VERSION ""

NS_ :

BS_:

BU_: Vector__XXX

BO_ 20 debugDTC: 5 Vector__XXX
SG_ DTC : 0|32@1+ (1,0) [0|4294967295] "" Vector__XXX
SG_ severity : 32|8@1+ (1,0) [0|255] "" Vector__XXX

BO_ 1703 lib_uds: 8 Vector__XXX
SG_ lib_uds_Mux M : 15|4@0+ (1,0) [0|0] "" Vector__XXX
SG_ isotp_n_ta : 7|8@0+ (1,0) [0|255] "" Vector__XXX
SG_ isotp_bs m3 : 23|8@0+ (1,0) [0|255] "" Vector__XXX
SG_ isotp_fs m3 : 11|4@0+ (1,0) [0|15] "" Vector__XXX
SG_ isotp_n_data_fc m3 : 39|32@0+ (1,0) [0|4294967295] "" Vector__XXX
SG_ isotp_stmin m3 : 31|8@0+ (1,0) [0|255] "ms" Vector__XXX
SG_ isotp_sn m2 : 11|4@0+ (1,0) [0|15] "" Vector__XXX
SG_ isotp_n_data_cf m2 : 23|48@0+ (1,0) [0|281474976710655] "" Vector__XXX
SG_ isotp_ff_dl m1 : 11|12@0+ (1,0) [0|4095] "" Vector__XXX
SG_ isotp_n_data_ff m1 : 31|40@0+ (1,0) [0|1099511627775] "" Vector__XXX
SG_ isotp_n_data_sf m0 : 23|48@0+ (1,0) [0|281474976710655] "" Vector__XXX
SG_ isotp_sf_dl m0 : 11|4@0+ (1,0) [0|15] "" Vector__XXX

BO_ 1447 lib_sdo_tx: 8 Vector__XXX
SG_ lib_sdo_tx_Mux M : 5|3@1+ (1,0) [0|0] "" Vector__XXX
SG_ canopen_sdo_abort_code m4 : 32|32@1+ (1,0) [0|4294967295] "" Vector__XXX
SG_ canopen_sdo_abort_index m4 : 8|16@1+ (1,0) [0|65535] "" Vector__XXX
SG_ canopen_sdo_abort_subindex m4 : 24|8@1+ (1,0) [0|255] "" Vector__XXX
SG_ canopen_sdo_upload_toggle_bit m0 : 4|1@1+ (1,0) [0|1] "" Vector__XXX
SG_ canopen_sdo_seg_data m0 : 8|56@1+ (1,0) [0|7.20575940379279E016] "" Vector__XXX
SG_ canopen_sdo_continue m0 : 0|1@1+ (1,0) [0|1] "" Vector__XXX
SG_ canopen_sdo_number_of_bytes_3 m0 : 1|3@1+ (1,0) [0|7] "" Vector__XXX
SG_ canopen_sdo_download_index m3 : 8|16@1+ (1,0) [0|65535] "" Vector__XXX
SG_ canopen_sdo_download_subindex m3 : 24|8@1+ (1,0) [0|255] "" Vector__XXX
SG_ canopen_sdo_upload_index m2 : 8|16@1+ (1,0) [0|65535] "" Vector__XXX
SG_ canopen_sdo_size_indicator m2 : 0|1@1+ (1,0) [0|1] "" Vector__XXX
SG_ canopen_sdo_data m2 : 32|32@1+ (1,0) [0|4294967295] "" Vector__XXX
SG_ canopen_sdo_transfer_type m2 : 1|1@1+ (1,0) [0|1] "" Vector__XXX
SG_ canopen_sdo_number_of_bytes_2 m2 : 2|2@1+ (1,0) [0|3] "" Vector__XXX
SG_ canopen_sdo_upload_subindex m2 : 24|8@1+ (1,0) [0|255] "" Vector__XXX
SG_ canopen_sdo_download_toggle_bit m1 : 4|1@1+ (1,0) [0|1] "" Vector__XXX

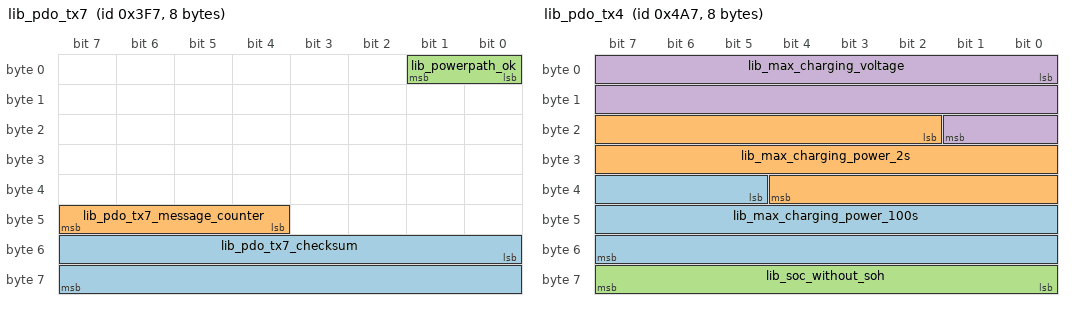
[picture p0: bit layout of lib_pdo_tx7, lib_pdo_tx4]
BO_ 1015 lib_pdo_tx7: 8 Vector__XXX
SG_ lib_pdo_tx7_checksum : 48|16@1+ (1,0) [0|65535] "" Vector__XXX
SG_ lib_pdo_tx7_message_counter : 44|4@1+ (1,0) [0|15] "" Vector__XXX
SG_ lib_powerpath_ok : 0|2@1+ (1,0) [0|3] "" Vector__XXX

BO_ 759 lib_pdo_tx6: 8 Vector__XXX
SG_ lib_max_charging_current_2s : 0|18@1+ (0.01,0) [0|2621.39] "A" Vector__XXX
SG_ lib_max_charging_current_100s : 18|18@1+ (0.01,0) [0|2621.39] "A" Vector__XXX

BO_ 503 lib_pdo_tx5: 8 Vector__XXX
SG_ lib_max_discharging_current_2s : 0|18@1+ (0.01,0) [0|2621.39] "A" Vector__XXX
SG_ lib_max_discharging_current_100s : 18|18@1+ (0.01,0) [0|2621.39] "A" Vector__XXX

BO_ 1191 lib_pdo_tx4: 8 Vector__XXX
SG_ lib_max_charging_power_100s : 37|19@1+ (1,0) [0|524283] "W" Vector__XXX
SG_ lib_max_charging_power_2s : 18|19@1+ (1,0) [0|524283] "W" Vector__XXX
SG_ lib_soc_without_soh : 56|8@1+ (0.5,0) [0|100] "%" Vector__XXX
SG_ lib_max_charging_voltage : 0|18@1+ (0.01,0) [0|2621.39] "V" Vector__XXX

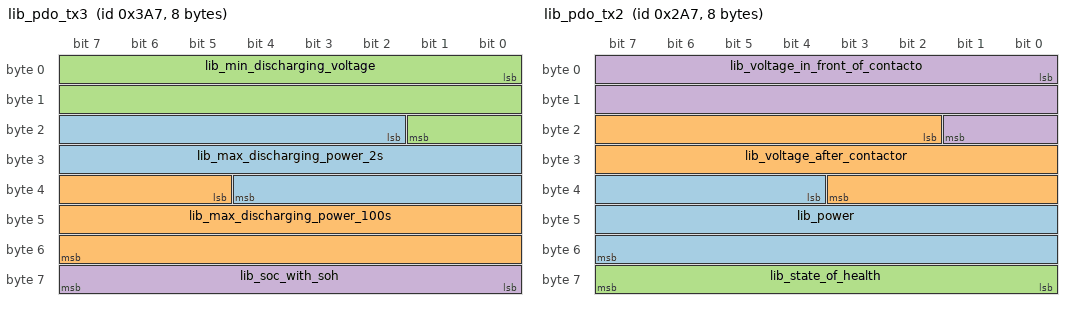
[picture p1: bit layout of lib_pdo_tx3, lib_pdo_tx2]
BO_ 935 lib_pdo_tx3: 8 Vector__XXX
SG_ lib_max_discharging_power_2s : 18|19@1+ (1,0) [0|524283] "W" Vector__XXX
SG_ lib_max_discharging_power_100s : 37|19@1+ (1,0) [0|524283] "W" Vector__XXX
SG_ lib_min_discharging_voltage : 0|18@1+ (0.01,0) [0|2621.39] "V" Vector__XXX
SG_ lib_soc_with_soh : 56|8@1+ (0.5,0) [0|100] "%" Vector__XXX

BO_ 679 lib_pdo_tx2: 8 Vector__XXX
SG_ lib_power : 36|20@1+ (1,-524286) [-524286|524285] "W" Vector__XXX
SG_ lib_voltage_after_contactor : 18|18@1+ (0.01,0) [0|2621.39] "V" Vector__XXX
SG_ lib_state_of_health : 56|8@1+ (0.5,0) [0|100] "%" Vector__XXX
SG_ lib_voltage_in_front_of_contacto : 0|18@1+ (0.01,0) [0|2621.39] "V" Vector__XXX

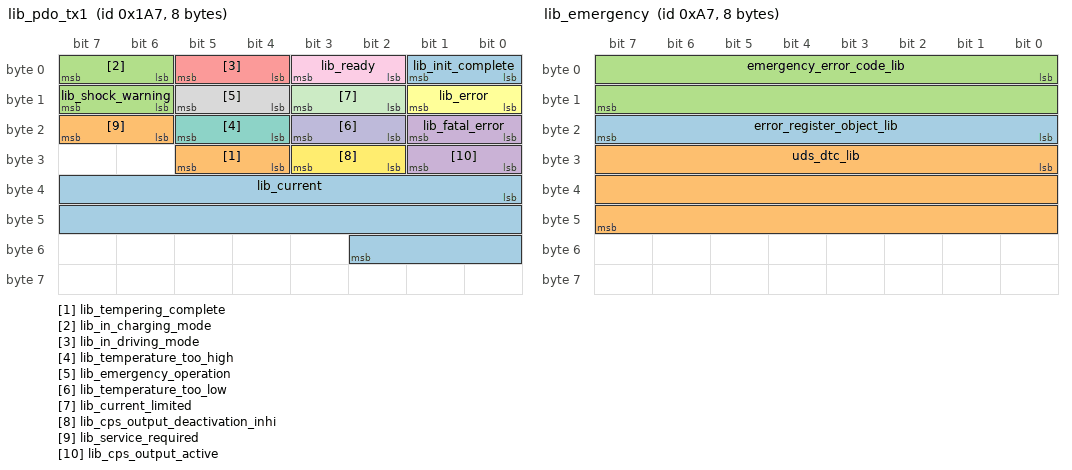
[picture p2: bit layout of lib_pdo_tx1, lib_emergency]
BO_ 423 lib_pdo_tx1: 8 Vector__XXX
SG_ lib_current : 32|19@1+ (0.01,-2621.42) [-2621.42|2621.41] "A" Vector__XXX
SG_ lib_tempering_complete : 28|2@1+ (1,0) [0|3] "" Vector__XXX
SG_ lib_in_charging_mode : 6|2@1+ (1,0) [0|3] "" Vector__XXX
SG_ lib_fatal_error : 16|2@1+ (1,0) [0|3] "" Vector__XXX
SG_ lib_in_driving_mode : 4|2@1+ (1,0) [0|3] "" Vector__XXX
SG_ lib_error : 8|2@1+ (1,0) [0|3] "" Vector__XXX
SG_ lib_temperature_too_high : 20|2@1+ (1,0) [0|3] "" Vector__XXX
SG_ lib_emergency_operation : 12|2@1+ (1,0) [0|3] "" Vector__XXX
SG_ lib_ready : 2|2@1+ (1,0) [0|3] "" Vector__XXX
SG_ lib_temperature_too_low : 18|2@1+ (1,0) [0|3] "" Vector__XXX
SG_ lib_current_limited : 10|2@1+ (1,0) [0|3] "" Vector__XXX
SG_ lib_cps_output_deactivation_inhi : 26|2@1+ (1,0) [0|3] "" Vector__XXX
SG_ lib_init_complete : 0|2@1+ (1,0) [0|3] "" Vector__XXX
SG_ lib_service_required : 22|2@1+ (1,0) [0|3] "" Vector__XXX
SG_ lib_shock_warning : 14|2@1+ (1,0) [0|3] "" Vector__XXX
SG_ lib_cps_output_active : 24|2@1+ (1,0) [0|3] "" Vector__XXX

BO_ 1831 lib_heartbeat: 1 Vector__XXX
SG_ canopen_state_lib : 0|7@1+ (1,0) [0|127] "" Vector__XXX

BO_ 167 lib_emergency: 8 Vector__XXX
SG_ error_register_object_lib : 16|8@1+ (1,0) [0|255] "" Vector__XXX
SG_ uds_dtc_lib : 24|24@1+ (1,0) [0|16777215] "" Vector__XXX
SG_ emergency_error_code_lib : 0|16@1+ (1,0) [0|65535] "" Vector__XXX

BO_ 1759 cps_uds: 8 Vector__XXX
SG_ cps_uds_Mux M : 15|4@0+ (1,0) [0|0] "" Vector__XXX
SG_ isotp_n_ta : 7|8@0+ (1,0) [0|255] "" Vector__XXX
SG_ isotp_fs m3 : 11|4@0+ (1,0) [0|15] "" Vector__XXX
SG_ isotp_bs m3 : 23|8@0+ (1,0) [0|255] "" Vector__XXX
SG_ isotp_n_data_fc m3 : 39|32@0+ (1,0) [0|4294967295] "" Vector__XXX
SG_ isotp_stmin m3 : 31|8@0+ (1,0) [0|255] "ms" Vector__XXX
SG_ isotp_ff_dl m1 : 11|12@0+ (1,0) [0|4095] "" Vector__XXX
SG_ isotp_n_data_ff m1 : 31|40@0+ (1,0) [0|1099511627775] "" Vector__XXX
SG_ isotp_sf_dl m0 : 11|4@0+ (1,0) [0|15] "" Vector__XXX
SG_ isotp_n_data_sf m0 : 23|48@0+ (1,0) [0|281474976710655] "" Vector__XXX
SG_ isotp_n_data_cf m2 : 23|48@0+ (1,0) [0|281474976710655] "" Vector__XXX
SG_ isotp_sn m2 : 11|4@0+ (1,0) [0|15] "" Vector__XXX

BO_ 1805 HeartbtBms: 1 Vector__XXX
SG_ stateBms : 0|7@1+ (1,0) [0|127] "" Vector__XXX

BO_ 1949 DiagRespBms: 8 Vector__XXX
SG_ BmsRsData : 8|56@1+ (1,0) [0|7.20575940379279E016] "" Vector__XXX
SG_ BmsRsPCI : 0|8@1+ (1,0) [0|255] "" Vector__XXX

BO_ 1421 BmsSDOtx: 8 Vector__XXX
SG_ BmsSDOtxData : 0|64@1+ (1,0) [0|1.84467440737096E019] "" Vector__XXX

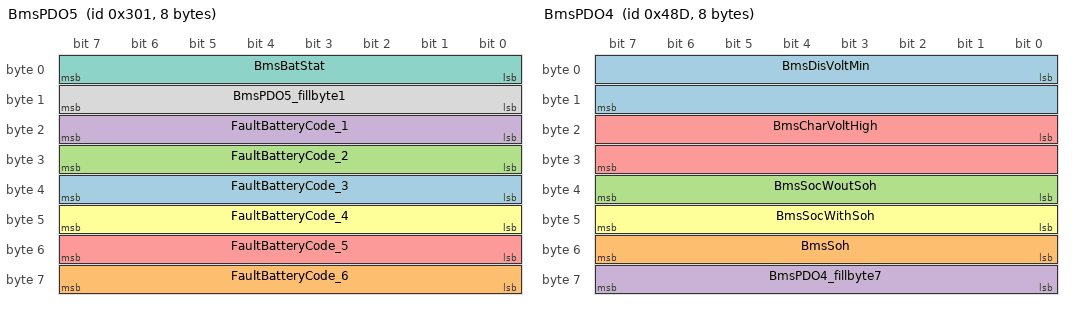
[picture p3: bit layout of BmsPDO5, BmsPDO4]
BO_ 769 BmsPDO5: 8 Vector__XXX
SG_ FaultBatteryCode_3 : 32|8@1+ (1,0) [0|255] "" Vector__XXX
SG_ FaultBatteryCode_6 : 56|8@1+ (1,0) [0|255] "" Vector__XXX
SG_ FaultBatteryCode_2 : 24|8@1+ (1,0) [0|255] "" Vector__XXX
SG_ FaultBatteryCode_1 : 16|8@1+ (1,0) [0|255] "" Vector__XXX
SG_ FaultBatteryCode_5 : 48|8@1+ (1,0) [0|255] "" Vector__XXX
SG_ FaultBatteryCode_4 : 40|8@1+ (1,0) [0|255] "" Vector__XXX
SG_ BmsBatStat : 0|8@1+ (1,0) [0|255] "" Vector__XXX
SG_ BmsPDO5_fillbyte1 : 8|8@1+ (1,0) [0|255] "" Vector__XXX

BO_ 1165 BmsPDO4: 8 Vector__XXX
SG_ BmsDisVoltMin : 0|16@1+ (25,0) [0|1638375] "mV" Vector__XXX
SG_ BmsSoh : 48|8@1+ (1,0) [0|100] "%" Vector__XXX
SG_ BmsSocWoutSoh : 32|8@1+ (1,0) [0|100] "%" Vector__XXX
SG_ BmsPDO4_fillbyte7 : 56|8@1- (1,0) [-128|127] "" Vector__XXX
SG_ BmsCharVoltHigh : 16|16@1+ (25,0) [0|1638375] "mV" Vector__XXX
SG_ BmsSocWithSoh : 40|8@1+ (1,0) [0|100] "%" Vector__XXX

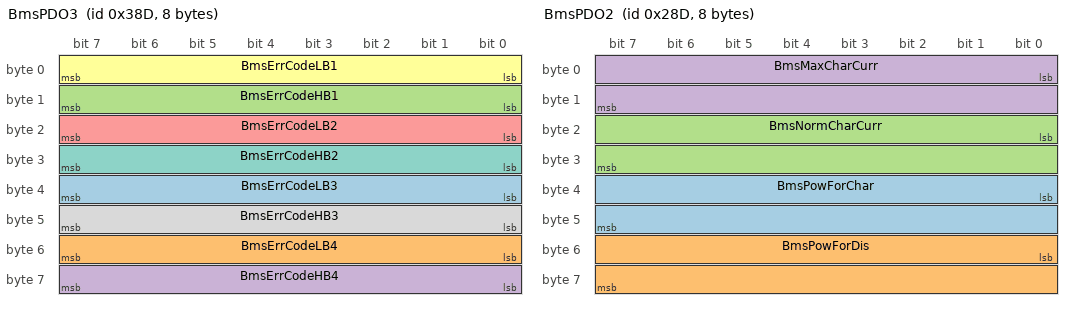
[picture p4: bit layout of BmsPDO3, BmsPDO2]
BO_ 909 BmsPDO3: 8 Vector__XXX
SG_ BmsErrCodeLB3 : 32|8@1+ (1,0) [0|255] "" Vector__XXX
SG_ BmsErrCodeLB4 : 48|8@1+ (1,0) [0|255] "" Vector__XXX
SG_ BmsErrCodeHB1 : 8|8@1+ (1,0) [0|255] "" Vector__XXX
SG_ BmsErrCodeHB4 : 56|8@1+ (1,0) [0|255] "" Vector__XXX
SG_ BmsErrCodeLB2 : 16|8@1+ (1,0) [0|255] "" Vector__XXX
SG_ BmsErrCodeLB1 : 0|8@1+ (1,0) [0|255] "" Vector__XXX
SG_ BmsErrCodeHB2 : 24|8@1+ (1,0) [0|255] "" Vector__XXX
SG_ BmsErrCodeHB3 : 40|8@1+ (1,0) [0|255] "" Vector__XXX

BO_ 653 BmsPDO2: 8 Vector__XXX
SG_ BmsPowForChar : 32|16@1+ (10,0) [0|655350] "W" Vector__XXX
SG_ BmsPowForDis : 48|16@1+ (10,0) [0|655350] "W" Vector__XXX
SG_ BmsNormCharCurr : 16|16@1+ (0.25,0) [0|16383.75] "A" Vector__XXX
SG_ BmsMaxCharCurr : 0|16@1+ (0.25,0) [0|16383.75] "A" Vector__XXX

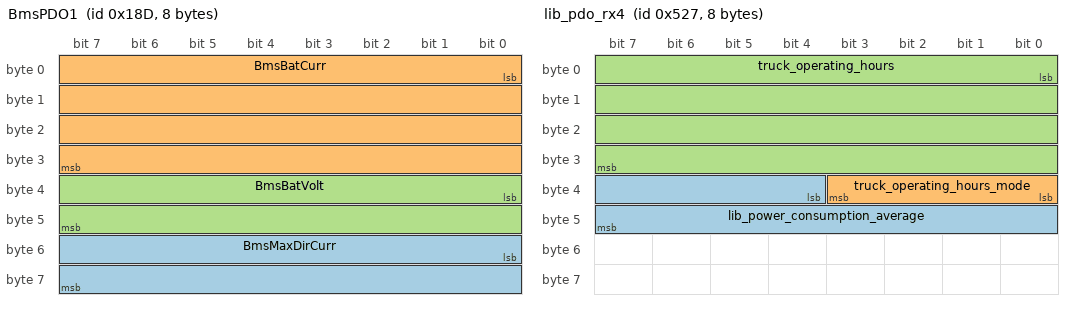
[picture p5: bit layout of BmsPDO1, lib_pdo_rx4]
BO_ 397 BmsPDO1: 8 Vector__XXX
SG_ BmsMaxDirCurr : 48|16@1+ (0.25,0) [0|16383.75] "A" Vector__XXX
SG_ BmsBatCurr : 0|32@1- (1,0) [-4000000|4000000] "mA" Vector__XXX
SG_ BmsBatVolt : 32|16@1+ (2,0) [0|131070] "mV" Vector__XXX

BO_ 1664 dtu_uds: 8 Vector__XXX
SG_ dtu_uds_Mux M : 15|4@0+ (1,0) [0|0] "" Vector__XXX
SG_ isotp_n_ta : 7|8@0+ (1,0) [0|255] "" Vector__XXX
SG_ isotp_n_data_fc m3 : 39|32@0+ (1,0) [0|4294967295] "" Vector__XXX
SG_ isotp_fs m3 : 11|4@0+ (1,0) [0|15] "" Vector__XXX
SG_ isotp_stmin m3 : 31|8@0+ (1,0) [0|255] "ms" Vector__XXX
SG_ isotp_bs m3 : 23|8@0+ (1,0) [0|255] "" Vector__XXX
SG_ isotp_sf_dl m0 : 11|4@0+ (1,0) [0|15] "" Vector__XXX
SG_ isotp_n_data_sf m0 : 23|48@0+ (1,0) [0|281474976710655] "" Vector__XXX
SG_ isotp_sn m2 : 11|4@0+ (1,0) [0|15] "" Vector__XXX
SG_ isotp_n_data_cf m2 : 23|48@0+ (1,0) [0|281474976710655] "" Vector__XXX
SG_ isotp_n_data_ff m1 : 31|40@0+ (1,0) [0|1099511627775] "" Vector__XXX
SG_ isotp_ff_dl m1 : 11|12@0+ (1,0) [0|4095] "" Vector__XXX

BO_ 256 time: 6 Vector__XXX
SG_ canopen_time_of_day_ms : 0|28@1+ (1,0) [0|268435455] "ms" Vector__XXX
SG_ canopen_time_of_day_days : 32|16@1+ (1,0) [0|65535] "d" Vector__XXX

BO_ 1873 obc_heartbeat: 1 Vector__XXX
SG_ canopen_state_obc : 1|7@1+ (1,0) [0|127] "" Vector__XXX

BO_ 0 module_control: 2 Vector__XXX
SG_ canopen_nmt_command_specifier : 0|8@1+ (1,0) [0|255] "" Vector__XXX
SG_ canopen_node_id : 8|8@1+ (1,0) [0|127] "" Vector__XXX

BO_ 1575 lib_sdo_rx: 8 Vector__XXX
SG_ lib_sdo_rx_Mux M : 5|3@1+ (1,0) [0|0] "" Vector__XXX
SG_ canopen_sdo_size_indicator m1 : 0|1@1+ (1,0) [0|1] "" Vector__XXX
SG_ canopen_sdo_number_of_bytes_2 m1 : 2|2@1+ (1,0) [0|3] "" Vector__XXX
SG_ canopen_sdo_download_index m1 : 8|16@1+ (1,0) [0|65535] "" Vector__XXX
SG_ canopen_sdo_transfer_type m1 : 1|1@1+ (1,0) [0|1] "" Vector__XXX
SG_ canopen_sdo_data m1 : 32|32@1+ (1,0) [0|4294967295] "" Vector__XXX
SG_ canopen_sdo_download_subindex m1 : 24|8@1+ (1,0) [0|255] "" Vector__XXX
SG_ canopen_sdo_abort_code m4 : 32|32@1+ (1,0) [0|4294967295] "" Vector__XXX
SG_ canopen_sdo_abort_index m4 : 8|16@1+ (1,0) [0|65535] "" Vector__XXX
SG_ canopen_sdo_abort_subindex m4 : 24|8@1+ (1,0) [0|255] "" Vector__XXX
SG_ canopen_sdo_upload_index m2 : 8|16@1+ (1,0) [0|65535] "" Vector__XXX
SG_ canopen_sdo_upload_subindex m2 : 24|8@1+ (1,0) [0|255] "" Vector__XXX
SG_ canopen_sdo_seg_data m0 : 8|56@1+ (1,0) [0|7.20575940379279E016] "" Vector__XXX
SG_ canopen_sdo_number_of_bytes_3 m0 : 1|3@1+ (1,0) [0|7] "" Vector__XXX
SG_ canopen_sdo_continue m0 : 0|1@1+ (1,0) [0|1] "" Vector__XXX
SG_ canopen_sdo_download_toggle_bit m0 : 4|1@1+ (1,0) [0|1] "" Vector__XXX
SG_ canopen_sdo_upload_toggle_bit m3 : 4|1@1+ (1,0) [0|1] "" Vector__XXX

BO_ 1319 lib_pdo_rx4: 8 Vector__XXX
SG_ lib_power_consumption_average : 36|12@1+ (0.05,-102.3) [-102.3|102.25] "kW" Vector__XXX
SG_ truck_operating_hours_mode : 32|4@1+ (1,0) [0|15] "" Vector__XXX
SG_ truck_operating_hours : 0|32@1+ (1,-36000) [-36000|4294931295] "s" Vector__XXX

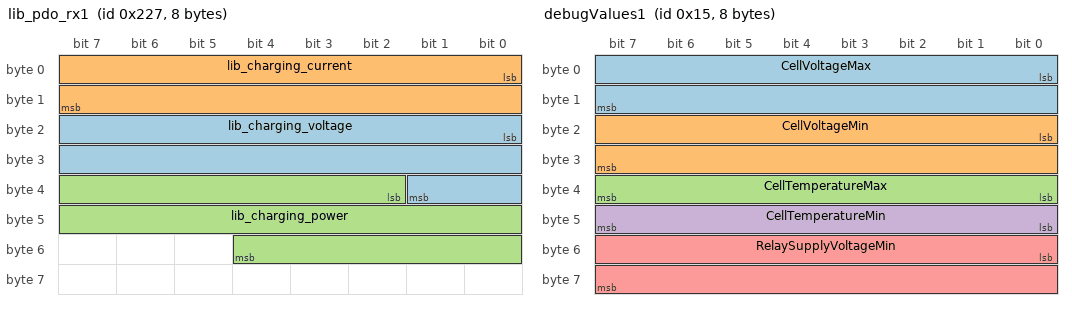
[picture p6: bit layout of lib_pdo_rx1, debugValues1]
BO_ 551 lib_pdo_rx1: 8 Vector__XXX
SG_ lib_charging_voltage : 16|18@1+ (0.01,0) [0|2621.39] "V" Vector__XXX
SG_ lib_charging_current : 0|16@1+ (0.01,0) [0|655.31] "A" Vector__XXX
SG_ lib_charging_power : 34|19@1+ (1,0) [0|524283] "W" Vector__XXX

BO_ 1793 kwpc_heartbeat: 1 Vector__XXX
SG_ canopen_state_kwpc : 1|7@1+ (1,0) [0|127] "" Vector__XXX

BO_ 1866 exc_heartbeat: 1 Vector__XXX
SG_ canopen_state_exc : 0|7@1+ (1,0) [0|127] "" Vector__XXX

BO_ 255 TimeStamp: 4 Vector__XXX
SG_ DateTime : 0|32@1+ (1,0) [0|4294967295] "s" Vector__XXX

BO_ 128 SYNC: 0 Vector__XXX

BO_ 1797 HeartbtLiionCharger: 1 Vector__XXX
SG_ stateLiionCharger : 0|7@1+ (1,0) [0|127] "" Vector__XXX

BO_ 1933 DiagReqBms: 8 Vector__XXX
SG_ BmsRqData : 8|56@1+ (1,0) [0|7.20575940379279E016] "" Vector__XXX
SG_ BmsRqPCI : 0|8@1+ (1,0) [0|255] "" Vector__XXX

BO_ 1549 BmsSDOrx: 8 Vector__XXX
SG_ BmsSDOrxData : 0|64@1+ (1,0) [0|1.84467440737096E019] "" Vector__XXX

BO_ 21 debugValues1: 8 Vector__XXX
SG_ CellVoltageMax : 0|16@1+ (1,0) [0|65535] "" Vector__XXX
SG_ CellVoltageMin : 16|16@1+ (1,0) [0|65535] "" Vector__XXX
SG_ CellTemperatureMax : 32|8@1- (1,0) [-128|127] "" Vector__XXX
SG_ CellTemperatureMin : 40|8@1- (1,0) [-128|127] "" Vector__XXX
SG_ RelaySupplyVoltageMin : 48|16@1+ (1,0) [0|65535] "" Vector__XXX

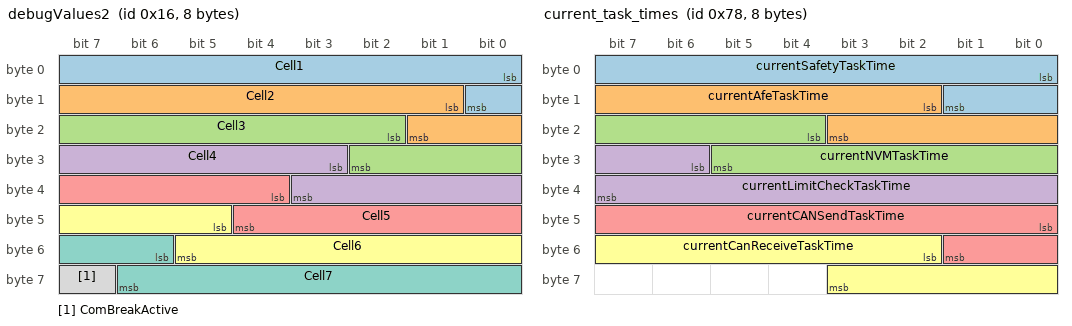
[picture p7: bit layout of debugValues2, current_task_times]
BO_ 22 debugValues2: 8 Vector__XXX
SG_ Cell1 : 0|9@1+ (10,0) [0|5110] "" Vector__XXX
SG_ Cell2 : 9|9@1+ (10,0) [0|5110] "" Vector__XXX
SG_ Cell3 : 18|9@1+ (10,0) [0|5110] "" Vector__XXX
SG_ Cell4 : 27|9@1+ (10,0) [0|5110] "" Vector__XXX
SG_ Cell5 : 36|9@1+ (10,0) [0|5110] "" Vector__XXX
SG_ Cell6 : 45|9@1+ (10,0) [0|5110] "" Vector__XXX
SG_ Cell7 : 54|9@1+ (10,0) [0|5110] "" Vector__XXX
SG_ ComBreakActive : 63|1@1+ (1,0) [0|1] "" Vector__XXX

BO_ 2633967613 lib_xcp_cmd: 0 Vector__XXX

BO_ 2634000381 lib_xcp_res: 0 Vector__XXX

BO_ 120 current_task_times: 8 Vector__XXX
SG_ currentSafetyTaskTime : 0|10@1+ (1,0) [0|1023] "cs" Vector__XXX
SG_ currentAfeTaskTime : 10|10@1+ (1,0) [0|1023] "cs" Vector__XXX
SG_ currentNVMTaskTime : 20|10@1+ (1,0) [0|1023] "cs" Vector__XXX
SG_ currentLimitCheckTaskTime : 30|10@1+ (1,0) [0|1023] "cs" Vector__XXX
SG_ currentCANSendTaskTime : 40|10@1+ (1,0) [0|1023] "cs" Vector__XXX
SG_ currentCanReceiveTaskTime : 50|10@1+ (1,0) [0|1023] "" Vector__XXX

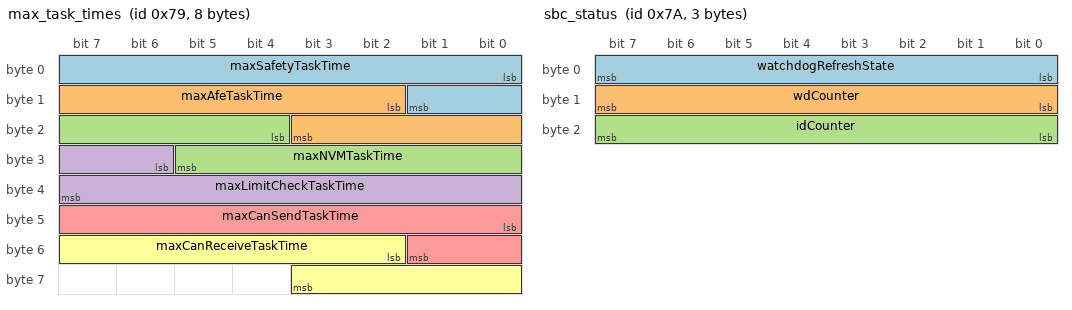
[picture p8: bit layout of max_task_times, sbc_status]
BO_ 121 max_task_times: 8 Vector__XXX
SG_ maxSafetyTaskTime : 0|10@1+ (1,0) [0|1023] "cs" Vector__XXX
SG_ maxAfeTaskTime : 10|10@1+ (1,0) [0|1023] "cs" Vector__XXX
SG_ maxNVMTaskTime : 20|10@1+ (1,0) [0|1023] "cs" Vector__XXX
SG_ maxLimitCheckTaskTime : 30|10@1+ (1,0) [0|1023] "cs" Vector__XXX
SG_ maxCanSendTaskTime : 40|10@1+ (1,0) [0|1023] "cs" Vector__XXX
SG_ maxCanReceiveTaskTime : 50|10@1+ (1,0) [0|1023] "cs" Vector__XXX

BO_ 122 sbc_status: 3 Vector__XXX
SG_ watchdogRefreshState : 0|8@1+ (1,0) [0|255] "" Vector__XXX
SG_ wdCounter : 8|8@1+ (1,0) [0|255] "" Vector__XXX
SG_ idCounter : 16|8@1+ (1,0) [0|255] "" Vector__XXX

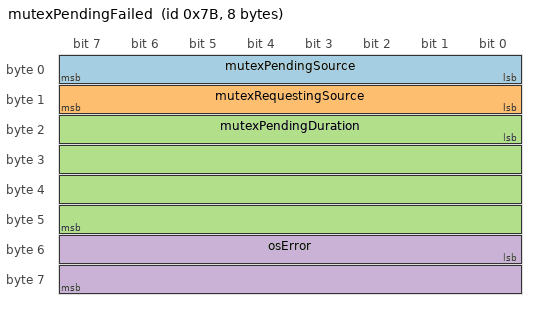
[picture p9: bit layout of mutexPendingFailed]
BO_ 123 mutexPendingFailed: 8 Vector__XXX
SG_ mutexPendingSource : 0|8@1+ (1,0) [0|255] "" Vector__XXX
SG_ mutexRequestingSource : 8|8@1+ (1,0) [0|255] "" Vector__XXX
SG_ mutexPendingDuration : 16|32@1+ (1,0) [0|4294967295] "ms" Vector__XXX
SG_ osError : 48|16@1- (1,0) [-32768|32767] "" Vector__XXX

BO_ 124 mutexPostFailed: 3 Vector__XXX
SG_ mutexPostSource : 0|8@1+ (1,0) [0|255] "" Vector__XXX
SG_ osError : 8|16@1- (1,0) [-32768|32767] "" Vector__XXX

CM_ BO_ 1703 "UDS responses from LIB with KION protocol";
CM_ SG_ 1703 lib_uds_Mux "network protocol control information type (ISO-TP extended addressing)";
CM_ SG_ 1703 isotp_n_ta "network target address (ISO-TP extended addressing)";
CM_ SG_ 1703 isotp_bs "FlowControl BlockSize (ISO-TP extended addressing)";
CM_ SG_ 1703 isotp_fs "FlowControl FlowStatus (ISO-TP extended addressing)";
CM_ SG_ 1703 isotp_n_data_fc "FlowControl Data Field (ISO-TP extended addressing)";
CM_ SG_ 1703 isotp_stmin "FlowControl SeparationTime minimum (ISO-TP extended addressing)";
CM_ SG_ 1703 isotp_sn "ConsecutiveFrame SequenceNumber (ISO-TP extended addressing)";
CM_ SG_ 1703 isotp_n_data_cf "Consecutive Frame Data Field (ISO-TP extended addressing)";
CM_ SG_ 1703 isotp_ff_dl "FirstFrame DataLength (ISO-TP extended addressing)";
CM_ SG_ 1703 isotp_n_data_ff "FirstFrame Data Field (ISO-TP extended addressing)";
CM_ SG_ 1703 isotp_n_data_sf "SingleFrame Data Field (ISO-TP extended addressing)";
CM_ SG_ 1703 isotp_sf_dl "SingleFrame DataLength (ISO-TP extended addressing)";
CM_ BO_ 1447 "SDO Tx, node 0x27 (LIB with KION protocol), SDO clients: KMC, OBC, EXC";
CM_ BO_ 1015 "PDO 7 (Tx), node 0x77 (LIB with KION protocol)";
CM_ BO_ 759 "PDO 6 (Tx), node 0x77 (LIB with KION protocol)";
CM_ BO_ 503 "PDO 5 (Tx), node 0x77 (LIB with KION protocol)";
CM_ BO_ 1191 "PDO 4 (Tx), node 0x27 (LIB with KION protocol)";
CM_ BO_ 935 "PDO 3 (Tx), node 0x27 (LIB with KION protocol)";
CM_ BO_ 679 "PDO 2 (Tx), node 0x27 (LIB with KION protocol)";
CM_ SG_ 679 lib_power "positive values = charging, negative values = discharging";
CM_ SG_ 679 lib_voltage_after_contactor "voltage after battery contactor (as seen from battery), i.e. truck side of contactor";
CM_ SG_ 679 lib_voltage_in_front_of_contacto "voltage in front of battery contactor (as seen from battery), i.e. battery side of contactor";
CM_ BO_ 423 "PDO 1 (Tx), node 0x27 (LIB with KION protocol)";
CM_ SG_ 423 lib_current "positive values = charging, negative values = discharging";
CM_ BO_ 1831 "heartbeat (NMT error control), node 0x27 (LIB with KION protocol)";
CM_ SG_ 1831 canopen_state_lib "CANopen node status of lithium-ion battery (KION protocol)";
CM_ BO_ 167 "emergency (EMCY), node 0x27 (LIB with KION protocol)";
CM_ BO_ 1759 "UDS responses from CPS in LIB with KION protocol";
CM_ SG_ 1759 cps_uds_Mux "network protocol control information type (ISO-TP extended addressing)";
CM_ SG_ 1759 isotp_n_ta "network target address (ISO-TP extended addressing)";
CM_ SG_ 1759 isotp_fs "FlowControl FlowStatus (ISO-TP extended addressing)";
CM_ SG_ 1759 isotp_bs "FlowControl BlockSize (ISO-TP extended addressing)";
CM_ SG_ 1759 isotp_n_data_fc "FlowControl Data Field (ISO-TP extended addressing)";
CM_ SG_ 1759 isotp_stmin "FlowControl SeparationTime minimum (ISO-TP extended addressing)";
CM_ SG_ 1759 isotp_ff_dl "FirstFrame DataLength (ISO-TP extended addressing)";
CM_ SG_ 1759 isotp_n_data_ff "FirstFrame Data Field (ISO-TP extended addressing)";
CM_ SG_ 1759 isotp_sf_dl "SingleFrame DataLength (ISO-TP extended addressing)";
CM_ SG_ 1759 isotp_n_data_sf "SingleFrame Data Field (ISO-TP extended addressing)";
CM_ SG_ 1759 isotp_n_data_cf "Consecutive Frame Data Field (ISO-TP extended addressing)";
CM_ SG_ 1759 isotp_sn "ConsecutiveFrame SequenceNumber (ISO-TP extended addressing)";
CM_ BO_ 1805 "Network Management, Error Control, Battery management system Heartbeat";
CM_ BO_ 1421 "CAN Open: Data for Service data object (SDO) send by BMS";
CM_ SG_ 1421 BmsSDOtxData "CAN Open: Data for Service data object (SDO) send by BMS";
CM_ SG_ 769 FaultBatteryCode_3 "Fault Battery Code # 3";
CM_ SG_ 769 FaultBatteryCode_6 "Fault Battery Code # 6";
CM_ SG_ 769 FaultBatteryCode_2 "Fault Battery Code # 2";
CM_ SG_ 769 FaultBatteryCode_1 "Fault Battery Code # 1";
CM_ SG_ 769 FaultBatteryCode_5 "Fault Battery Code # 5";
CM_ SG_ 769 FaultBatteryCode_4 "Fault Battery Code # 4";
CM_ SG_ 769 BmsPDO5_fillbyte1 "place holder to reserve signal position for future use";
CM_ SG_ 1165 BmsDisVoltMin "Minimum allowed voltage during discharge";
CM_ SG_ 1165 BmsPDO4_fillbyte7 "place holder to reserve signal position for future use";
CM_ SG_ 1165 BmsCharVoltHigh "Highest allowed voltage during charging";
CM_ SG_ 909 BmsErrCodeLB3 "BmsErrorCode3 (unsigned16, low byte)";
CM_ SG_ 909 BmsErrCodeLB4 "BmsErrorCode4 (unsigned16, low byte)";
CM_ SG_ 909 BmsErrCodeHB1 "BmsErrorCode1 (unsigned16, high byte)";
CM_ SG_ 909 BmsErrCodeHB4 "BmsErrorCode4 (unsigned16, high byte)";
CM_ SG_ 909 BmsErrCodeLB2 "BmsErrorCode2 (unsigned16, low byte)";
CM_ SG_ 909 BmsErrCodeLB1 "BmsErrorCode1 (unsigned16, low byte)";
CM_ SG_ 909 BmsErrCodeHB2 "BmsErrorCode2 (unsigned16, high byte)";
CM_ SG_ 909 BmsErrCodeHB3 "BmsErrorCode3 (unsigned16, high byte)";
CM_ SG_ 653 BmsPowForChar "Power forecasting: charging [W] = BmsPowForChar * 10";
CM_ SG_ 653 BmsPowForDis "Power forecasting: charging [W] = BmsPowForChar * 10";
CM_ SG_ 653 BmsNormCharCurr "Normal charge current [A] = BmsNormCharCurr * 0.25";
CM_ SG_ 653 BmsMaxCharCurr "Maximal charge current [A] = BmsMaxCharCurr * 0.25";
CM_ BO_ 1664 "UDS requests from DTU";
CM_ SG_ 1664 dtu_uds_Mux "network protocol control information type (ISO-TP extended addressing)";
CM_ SG_ 1664 isotp_n_ta "network target address (ISO-TP extended addressing)";
CM_ SG_ 1664 isotp_n_data_fc "FlowControl Data Field (ISO-TP extended addressing)";
CM_ SG_ 1664 isotp_fs "FlowControl FlowStatus (ISO-TP extended addressing)";
CM_ SG_ 1664 isotp_stmin "FlowControl SeparationTime minimum (ISO-TP extended addressing)";
CM_ SG_ 1664 isotp_bs "FlowControl BlockSize (ISO-TP extended addressing)";
CM_ SG_ 1664 isotp_sf_dl "SingleFrame DataLength (ISO-TP extended addressing)";
CM_ SG_ 1664 isotp_n_data_sf "SingleFrame Data Field (ISO-TP extended addressing)";
CM_ SG_ 1664 isotp_sn "ConsecutiveFrame SequenceNumber (ISO-TP extended addressing)";
CM_ SG_ 1664 isotp_n_data_cf "Consecutive Frame Data Field (ISO-TP extended addressing)";
CM_ SG_ 1664 isotp_n_data_ff "FirstFrame Data Field (ISO-TP extended addressing)";
CM_ SG_ 1664 isotp_ff_dl "FirstFrame DataLength (ISO-TP extended addressing)";
CM_ BO_ 256 "time stamp (TIME)";
CM_ BO_ 1873 "heartbeat (NMT error control), node 0x51 (OBC)";
CM_ SG_ 1873 canopen_state_obc "CANopen node status of on-board charger";
CM_ BO_ 0 "network management (NMT)";
CM_ BO_ 1575 "SDO Rx, node 0x27 (LIB with KION protocol), SDO clients: KMC, OBC, EXC";
CM_ BO_ 1319 "PDO 4 (Rx), node 0x27 (LIB with KION protocol)";
CM_ SG_ 1319 lib_power_consumption_average "for estimation of remaining charging time until end of shift";
CM_ SG_ 1319 truck_operating_hours_mode "main truck hour meter counting mode";
CM_ SG_ 1319 truck_operating_hours "main truck hour meter";
CM_ BO_ 551 "PDO 1 (Rx), node 0x27 (LIB with KION protocol)";
CM_ SG_ 551 lib_charging_voltage "output voltage of charger";
CM_ SG_ 551 lib_charging_current "output current of charger";
CM_ SG_ 551 lib_charging_power "output power of charger";
CM_ BO_ 1793 "heartbeat (NMT error control), node 0x01 (KWPC)";
CM_ SG_ 1793 canopen_state_kwpc "CANopen node status of KION Motion Controller";
CM_ BO_ 1866 "heartbeat (NMT error control), node 0x4A (EXC)";
CM_ SG_ 1866 canopen_state_exc "CANopen node status of the external battery charger";
CM_ BO_ 255 "Linde proprietary timestamp message (for LIB with Linde SAFT protocol)";
CM_ BO_ 128 "CANopen SYNC message (for LIB with Linde BMZ protocol)";
CM_ BO_ 1797 "Network Management, Error Control,  liion battery charger Heartbeat";
CM_ BO_ 1549 "CAN Open: Service data object (SDO) send by KWPC";
CM_ SG_ 1549 BmsSDOrxData "CAN Open: Data for Service data object (SDO) send by LAC";
CM_ BO_ 120 "shows times of every task in taskAliveMonitor";
CM_ SG_ 120 currentSafetyTaskTime "current cycle time of safety task";
CM_ SG_ 120 currentAfeTaskTime "current cycle time of afe task";
CM_ SG_ 120 currentNVMTaskTime "current cycle time of nvm task";
CM_ SG_ 120 currentLimitCheckTaskTime "current cycle time of limitCheck task";
CM_ SG_ 120 currentCANSendTaskTime "current cycle time of can send task";
CM_ SG_ 120 currentCanReceiveTaskTime "current cycle time of can receive task";
CM_ SG_ 121 maxSafetyTaskTime "max cycle time of safety task";
CM_ SG_ 121 maxAfeTaskTime "max cycle time of afe task";
CM_ SG_ 121 maxNVMTaskTime "max cycle time of NVM task";
CM_ SG_ 121 maxLimitCheckTaskTime "max cycle time of limitCheck task";
CM_ SG_ 121 maxCanSendTaskTime "max cycle time of can send task";
CM_ SG_ 121 maxCanReceiveTaskTime "max cycle time of can receive task";
CM_ SG_ 122 watchdogRefreshState "state of watchdog during SW reset call";
CM_ SG_ 122 wdCounter "watchdog counter";
CM_ SG_ 122 idCounter "idCounter of failed task in taskAliveMonitor";
CM_ BO_ 123 "mutex analysis data";
CM_ SG_ 123 mutexPendingSource "source of mutex that is currently pending";
CM_ SG_ 123 mutexRequestingSource "source of mutex pend request that is currently unsuccessful";
CM_ SG_ 123 mutexPendingDuration "duration of current pending time of the mutex in ms";
CM_ SG_ 123 osError "osError that was returned during mutex pend request";
CM_ BO_ 124 "failed mutex post analysis Signal";
CM_ SG_ 124 mutexPostSource "source of mutex post request";
CM_ SG_ 124 osError "OS error that was thrown during mutex post request";

BA_DEF_  "BusType" STRING ;
BA_DEF_ BO_  "GenMsgCycleTime" INT 0 65535;
BA_DEF_ SG_  "GenSigStartValue" FLOAT -3.4E+038 3.4E+038;

BA_DEF_DEF_  "BusType" "CAN";
BA_DEF_DEF_  "GenMsgCycleTime" 0;
BA_DEF_DEF_  "GenSigStartValue" 0;

BA_ "GenMsgCycleTime" BO_ 120 10;

BA_ "GenSigStartValue" SG_ 1015 lib_powerpath_ok 3;
BA_ "GenSigStartValue" SG_ 679 lib_power 524286;
BA_ "GenSigStartValue" SG_ 423 lib_tempering_complete 3;
BA_ "GenSigStartValue" SG_ 423 lib_in_charging_mode 3;
BA_ "GenSigStartValue" SG_ 423 lib_fatal_error 3;
BA_ "GenSigStartValue" SG_ 423 lib_in_driving_mode 3;
BA_ "GenSigStartValue" SG_ 423 lib_error 3;
BA_ "GenSigStartValue" SG_ 423 lib_temperature_too_high 3;
BA_ "GenSigStartValue" SG_ 423 lib_emergency_operation 3;
BA_ "GenSigStartValue" SG_ 423 lib_ready 3;
BA_ "GenSigStartValue" SG_ 423 lib_temperature_too_low 3;
BA_ "GenSigStartValue" SG_ 423 lib_current_limited 3;
BA_ "GenSigStartValue" SG_ 423 lib_cps_output_deactivation_inhi 3;
BA_ "GenSigStartValue" SG_ 423 lib_init_complete 3;
BA_ "GenSigStartValue" SG_ 423 lib_service_required 3;
BA_ "GenSigStartValue" SG_ 423 lib_shock_warning 3;
BA_ "GenSigStartValue" SG_ 423 lib_cps_output_active 3;
BA_ "GenSigStartValue" SG_ 1831 canopen_state_lib 127;
BA_ "GenSigStartValue" SG_ 1319 lib_power_consumption_average 2046;
BA_ "GenSigStartValue" SG_ 1319 truck_operating_hours_mode 15;
BA_ "GenSigStartValue" SG_ 1319 truck_operating_hours 36000;

VAL_ 1703 lib_uds_Mux 3 "flow control" 2 "consecutive frame" 1 "first frame" 0 "single frame" 7 "reserved 4" 6 "reserved 3" 5 "reserved 2" 4 "reserved 1";
VAL_ 1447 lib_sdo_tx_Mux 4 "abort transfer request" 0 "upload segment response" 3 "initiate download response" 2 "initiate upload response" 1 "download segment response" 7 "reserved" 6 "block upload" 5 "block download";
VAL_ 1759 cps_uds_Mux 3 "flow control" 1 "first frame" 0 "single frame" 2 "consecutive frame" 7 "reserved 4" 6 "reserved 3" 5 "reserved 2" 4 "reserved 1";
VAL_ 1664 dtu_uds_Mux 3 "flow control" 0 "single frame" 2 "consecutive frame" 1 "first frame" 7 "reserved 4" 6 "reserved 3" 5 "reserved 2" 4 "reserved 1";
VAL_ 1575 lib_sdo_rx_Mux 1 "initiate download request" 4 "abort transfer request" 2 "initiate upload request" 0 "download segment request" 3 "upload segment request" 7 "reserved" 6 "block download" 5 "block upload";
VAL_ 1703 isotp_n_ta 254 "functional address" 95 "cps" 81 "obc" 80 "knc" 72 "kwc_b" 70 "tpi" 68 "kap_r" 39 "lib" 38 "tu" 37 "kec" 33 "kcs" 32 "kcu" 31 "kap_k" 22 "dou" 20 "rpb" 19 "kwc_a" 18 "kae" 16 "ksc" 13 "kpc_l2" 12 "kpc_l1" 11 "kpc_tr" 10 "kpc_tl" 9 "kpc_u" 5 "kbc" 1 "kmc/kwpc" 0 "dtu";
VAL_ 1703 isotp_fs 15 "reserved 13" 14 "reserved 12" 13 "reserved 11" 12 "reserved 10" 11 "reserved 9" 10 "reserved 8" 9 "reserved 7" 8 "reserved 6" 7 "reserved 5" 6 "reserved 4" 5 "reserved 3" 4 "reserved 2" 3 "reserved 1" 2 "overflow" 1 "wait" 0 "continue to send";
VAL_ 1447 canopen_sdo_abort_code 134217764 "no data available" 134217763 "object dictionary dynamic generation fails or no dictionary present" 134217762 "data cannot be stored to the application because of the present device state" 134217761 "data cannot be stored to the application because of local control" 134217760 "data cannot be stored to the application" 134217728 "general error" 101318691 "resource not available: SDO connection" 101253174 "maximum value is less than minimum value" 101253170 "value of parameter written too low" 101253169 "value of parameter written too high" 101253168 "invalid value for parameter" 101253137 "subindex does not exist" 101122067 "data type mismatch, length of parameter too low" 101122066 "data type mismatch, length of parameter too high" 101122064 "data type mismatch, length of parameter does not match" 101056512 "access failed due to an hardware error" 100925511 "general internal incompatibility in the device" 100925507 "general parameter incompatibility reason" 100925506 "PDO length exceeded by mapping"
100925505 "object cannot be mapped to the PDO" 100794368 "object does not exist in the object dictionary" 100728834 "attempt to write a read only object" 100728833 "attempt to read a write only object" 100728832 "unsupported access to an object" 84148229 "out of memory" 84148228 "CRC error" 84148227 "invalid sequence number" 84148226 "invalid block size" 84148225 "client/server command specifier not valid or unknown" 84148224 "SDO protocol timed out" 84082688 "toggle bit not alternated";
VAL_ 1447 canopen_sdo_continue 1 "no more segments to be downloaded" 0 "more segments to be downloaded";
VAL_ 1447 canopen_sdo_number_of_bytes_3 7 "data length 0 byte" 6 "data length 1 byte" 5 "data length 2 byte" 4 "data length 3 byte" 3 "data length 4 byte" 2 "data length 5 byte" 1 "data length 6 byte" 0 "data length 7 byte";
VAL_ 1447 canopen_sdo_size_indicator 1 "data set size is indicated" 0 "data set size is not indicated";
VAL_ 1447 canopen_sdo_transfer_type 1 "expedited transfer" 0 "normal transfer";
VAL_ 1447 canopen_sdo_number_of_bytes_2 3 "data length 1 byte" 2 "data length 2 byte" 1 "data length 3 byte" 0 "data length 4 byte";
VAL_ 1015 lib_powerpath_ok 3 "signal not available" 2 "signal error" 1 "true/on" 0 "false/off";
VAL_ 759 lib_max_charging_current_2s 262143 "signal not available" 262142 "signal error" 262141 "reserved 2" 262140 "reserved 1";
VAL_ 759 lib_max_charging_current_100s 262143 "signal not available" 262142 "signal error" 262141 "reserved 2" 262140 "reserved 1";
VAL_ 503 lib_max_discharging_current_2s 262143 "signal not available" 262142 "signal error" 262141 "reserved 2" 262140 "reserved 1";
VAL_ 503 lib_max_discharging_current_100s 262143 "signal not available" 262142 "signal error" 262141 "reserved 2" 262140 "reserved 1";
VAL_ 1191 lib_max_charging_power_100s 524287 "signal not available" 524286 "signal error" 524285 "reserved 2" 524284 "reserved 1";
VAL_ 1191 lib_max_charging_power_2s 524287 "signal not available" 524286 "signal error" 524285 "reserved 2" 524284 "reserved 1";
VAL_ 1191 lib_soc_without_soh 255 "signal not available" 254 "signal error" 253 "reserved 2" 252 "reserved 1";
VAL_ 1191 lib_max_charging_voltage 262143 "signal not available" 262142 "signal error" 262141 "reserved 2" 262140 "reserved 1";
VAL_ 935 lib_max_discharging_power_2s 524287 "signal not available" 524286 "signal error" 524285 "reserved 2" 524284 "reserved 1";
VAL_ 935 lib_max_discharging_power_100s 524287 "signal not available" 524286 "signal error" 524285 "reserved 2" 524284 "reserved 1";
VAL_ 935 lib_min_discharging_voltage 262143 "signal not available" 262142 "signal error" 262141 "reserved 2" 262140 "reserved 1";
VAL_ 935 lib_soc_with_soh 255 "signal not available" 254 "signal error" 253 "reserved 2" 252 "reserved 1";
VAL_ 679 lib_power 1048575 "signal not available" 1048574 "signal error" 1048573 "reserved 2" 1048572 "reserved 1";
VAL_ 679 lib_voltage_after_contactor 262143 "signal not available" 262142 "signal error" 262141 "reserved 2" 262140 "reserved 1";
VAL_ 679 lib_state_of_health 255 "signal not available" 254 "signal error" 253 "reserved 2" 252 "reserved 1";
VAL_ 679 lib_voltage_in_front_of_contacto 262143 "signal not available" 262142 "signal error" 262141 "reserved 2" 262140 "reserved 1";
VAL_ 423 lib_current 524287 "signal not available" 524286 "signal error" 524285 "reserved 2" 524284 "reserved 1";
VAL_ 423 lib_tempering_complete 3 "signal not available" 2 "signal error" 1 "true/on" 0 "false/off";
VAL_ 423 lib_in_charging_mode 3 "signal not available" 2 "signal error" 1 "true/on" 0 "false/off";
VAL_ 423 lib_fatal_error 3 "signal not available" 2 "signal error" 1 "true/on" 0 "false/off";
VAL_ 423 lib_in_driving_mode 3 "signal not available" 2 "signal error" 1 "true/on" 0 "false/off";
VAL_ 423 lib_error 3 "signal not available" 2 "signal error" 1 "true/on" 0 "false/off";
VAL_ 423 lib_temperature_too_high 3 "signal not available" 2 "signal error" 1 "true/on" 0 "false/off";
VAL_ 423 lib_emergency_operation 3 "signal not available" 2 "signal error" 1 "true/on" 0 "false/off";
VAL_ 423 lib_ready 3 "signal not available" 2 "signal error" 1 "true/on" 0 "false/off";
VAL_ 423 lib_temperature_too_low 3 "signal not available" 2 "signal error" 1 "true/on" 0 "false/off";
VAL_ 423 lib_current_limited 3 "signal not available" 2 "signal error" 1 "true/on" 0 "false/off";
VAL_ 423 lib_cps_output_deactivation_inhi 3 "signal not available" 2 "signal error" 1 "true/on" 0 "false/off";
VAL_ 423 lib_init_complete 3 "signal not available" 2 "signal error" 1 "true/on" 0 "false/off";
VAL_ 423 lib_service_required 3 "signal not available" 2 "signal error" 1 "true/on" 0 "false/off";
VAL_ 423 lib_shock_warning 3 "signal not available" 2 "signal error" 1 "true/on" 0 "false/off";
VAL_ 423 lib_cps_output_active 3 "signal not available" 2 "signal error" 1 "true/on" 0 "false/off";
VAL_ 1831 canopen_state_lib 127 "pre-operational" 5 "operational" 4 "stopped" 0 "bootup";
VAL_ 1759 isotp_n_ta 254 "functional address" 95 "cps" 81 "obc" 80 "knc" 72 "kwc_b" 70 "tpi" 68 "kap_r" 39 "lib" 38 "tu" 37 "kec" 33 "kcs" 32 "kcu" 31 "kap_k" 22 "dou" 20 "rpb" 19 "kwc_a" 18 "kae" 16 "ksc" 13 "kpc_l2" 12 "kpc_l1" 11 "kpc_tr" 10 "kpc_tl" 9 "kpc_u" 5 "kbc" 1 "kmc/kwpc" 0 "dtu";
VAL_ 1759 isotp_fs 15 "reserved 13" 14 "reserved 12" 13 "reserved 11" 12 "reserved 10" 11 "reserved 9" 10 "reserved 8" 9 "reserved 7" 8 "reserved 6" 7 "reserved 5" 6 "reserved 4" 5 "reserved 3" 4 "reserved 2" 3 "reserved 1" 2 "overflow" 1 "wait" 0 "continue to send";
VAL_ 1805 stateBms 127 "PREOPERATIONAL" 5 "OPERATIONAL" 4 "STOPPED" 0 "BOOTUP";
VAL_ 769 FaultBatteryCode_3 7 "fault code status n� 24" 6 "fault code status n� 23" 5 "fault code status n� 22" 4 "fault code status n� 21" 3 "fault code status n� 20" 2 "fault code status n� 19" 1 "fault code status n� 18" 0 "fault code status n� 17";
VAL_ 769 FaultBatteryCode_6 7 "fault code status n� 48" 6 "fault code status n� 47" 5 "fault code status n� 46" 4 "fault code status n� 45" 3 "fault code status n� 44" 2 "fault code status n� 43" 1 "fault code status n� 42" 0 "fault code status n� 41";
VAL_ 769 FaultBatteryCode_2 7 "fault code status n� 16" 6 "fault code status n� 15" 5 "fault code status n� 14" 4 "fault code status n� 13" 3 "fault code status n� 12" 2 "fault code status n� 11" 1 "fault code status n� 10" 0 "fault code status n� 9";
VAL_ 769 FaultBatteryCode_1 7 "fault code status n� 8" 6 "fault code status n� 7" 5 "fault code status n� 6" 4 "fault code status n� 5" 3 "fault code status n� 4" 2 "fault code status n� 3" 1 "fault code status n� 2" 0 "fault code status n� 1";
VAL_ 769 FaultBatteryCode_5 7 "fault code status n� 40" 6 "fault code status n� 39" 5 "fault code status n� 38" 4 "fault code status n� 37" 3 "fault code status n� 36" 2 "fault code status n� 35" 1 "fault code status n� 34" 0 "fault code status n� 33";
VAL_ 769 FaultBatteryCode_4 7 "fault code status n� 32" 6 "fault code status n� 31" 5 "fault code status n� 30" 4 "fault code status n� 29" 3 "fault code status n� 28" 2 "fault code status n� 27" 1 "fault code status n� 26" 0 "fault code status n� 25";
VAL_ 769 BmsBatStat 9 "-> 0xFF reserved" 8 "Charge mode in regeneration" 7 "Charge- or On-board charge-mode" 6 "After run mode (self-test)" 5 "Safe mode (system disconnected)" 4 "Init mode (before precharge)" 3 "Standby mode" 2 "Pre-charge mode  " 1 "Nominal mode " 0 "Reserved";
VAL_ 1664 isotp_n_ta 254 "functional address" 95 "cps" 81 "obc" 80 "knc" 72 "kwc_b" 70 "tpi" 68 "kap_r" 39 "lib" 38 "tu" 37 "kec" 33 "kcs" 32 "kcu" 31 "kap_k" 22 "dou" 20 "rpb" 19 "kwc_a" 18 "kae" 16 "ksc" 13 "kpc_l2" 12 "kpc_l1" 11 "kpc_tr" 10 "kpc_tl" 9 "kpc_u" 5 "kbc" 1 "kmc/kwpc" 0 "dtu";
VAL_ 1664 isotp_fs 15 "reserved 13" 14 "reserved 12" 13 "reserved 11" 12 "reserved 10" 11 "reserved 9" 10 "reserved 8" 9 "reserved 7" 8 "reserved 6" 7 "reserved 5" 6 "reserved 4" 5 "reserved 3" 4 "reserved 2" 3 "reserved 1" 2 "overflow" 1 "wait" 0 "continue to send";
VAL_ 1873 canopen_state_obc 127 "pre-operational" 5 "operational" 4 "stopped" 0 "bootup";
VAL_ 0 canopen_nmt_command_specifier 130 "reset communication" 129 "reset node" 128 "enter pre-operational" 2 "stop remote node" 1 "start remote node";
VAL_ 0 canopen_node_id 81 "obc" 80 "knc" 76 "tci" 74 "exc" 70 "tpi" 68 "kap_r" 39 "lib" 38 "tu" 37 "kec" 33 "kcs" 32 "kcu" 31 "kap_k" 29 "lhs_r_b" 28 "lhs_r_a" 22 "dou" 20 "rpb" 18 "kae" 16 "ksc" 13 "kpc_l2" 12 "kpc_l1" 11 "kpc_tr" 10 "kpc_tl" 9 "kpc_u" 5 "kbc" 1 "kmc" 0 "all nodes";
VAL_ 1575 canopen_sdo_size_indicator 1 "data set size is indicated" 0 "data set size is not indicated";
VAL_ 1575 canopen_sdo_number_of_bytes_2 3 "data length 1 byte" 2 "data length 2 byte" 1 "data length 3 byte" 0 "data length 4 byte";
VAL_ 1575 canopen_sdo_transfer_type 1 "expedited transfer" 0 "normal transfer";
VAL_ 1575 canopen_sdo_abort_code 134217764 "no data available" 134217763 "object dictionary dynamic generation fails or no dictionary present" 134217762 "data cannot be stored to the application because of the present device state" 134217761 "data cannot be stored to the application because of local control" 134217760 "data cannot be stored to the application" 134217728 "general error" 101318691 "resource not available: SDO connection" 101253174 "maximum value is less than minimum value" 101253170 "value of parameter written too low" 101253169 "value of parameter written too high" 101253168 "invalid value for parameter" 101253137 "subindex does not exist" 101122067 "data type mismatch, length of parameter too low" 101122066 "data type mismatch, length of parameter too high" 101122064 "data type mismatch, length of parameter does not match" 101056512 "access failed due to an hardware error" 100925511 "general internal incompatibility in the device" 100925507 "general parameter incompatibility reason" 100925506 "PDO length exceeded by mapping"
100925505 "object cannot be mapped to the PDO" 100794368 "object does not exist in the object dictionary" 100728834 "attempt to write a read only object" 100728833 "attempt to read a write only object" 100728832 "unsupported access to an object" 84148229 "out of memory" 84148228 "CRC error" 84148227 "invalid sequence number" 84148226 "invalid block size" 84148225 "client/server command specifier not valid or unknown" 84148224 "SDO protocol timed out" 84082688 "toggle bit not alternated";
VAL_ 1575 canopen_sdo_number_of_bytes_3 7 "data length 0 byte" 6 "data length 1 byte" 5 "data length 2 byte" 4 "data length 3 byte" 3 "data length 4 byte" 2 "data length 5 byte" 1 "data length 6 byte" 0 "data length 7 byte";
VAL_ 1575 canopen_sdo_continue 1 "no more segments to be downloaded" 0 "more segments to be downloaded";
VAL_ 1319 lib_power_consumption_average 4095 "signal not available" 4094 "signal error" 4093 "reserved 2" 4092 "reserved 1";
VAL_ 1319 truck_operating_hours_mode 15 "signal not available" 14 "signal error" 13 "reserved 2" 12 "reserved 1" 8 "LIB charger operating hours" 7 "mode h engine running" 6 "mode g traction or lift motor active except lowering" 5 "mode f more than 50 W" 4 "mode e traction or lift motor active" 3 "mode d lift motor active" 2 "mode c traction motor active" 1 "mode b key switch" 0 "mode a key and seat switch";
VAL_ 1319 truck_operating_hours -1 "signal not available" -2 "signal error" -3 "reserved 2" -4 "reserved 1";
VAL_ 551 lib_charging_voltage 262143 "signal not available" 262142 "signal error" 262141 "reserved 2" 262140 "reserved 1";
VAL_ 551 lib_charging_current 65535 "signal not available" 65534 "signal error" 65533 "reserved 2" 65532 "reserved 1";
VAL_ 551 lib_charging_power 524287 "signal not available" 524286 "signal error" 524285 "reserved 2" 524284 "reserved 1";
VAL_ 1793 canopen_state_kwpc 127 "pre-operational" 5 "operational" 4 "stopped" 0 "bootup";
VAL_ 1866 canopen_state_exc 127 "pre-operational" 5 "operational" 4 "stopped" 0 "bootup";
VAL_ 1797 stateLiionCharger 127 "PREOPERATIONAL" 5 "OPERATIONAL" 4 "STOPPED" 0 "BOOTUP";
VAL_ 123 mutexPendingSource 0 "ADC_REQUEST_VOLTAGE" 1 "ADC_GET_RESULT" 2 "EEPROM_READ" 3 "EEPROM_WRITE" 4 "EEPROM_SUB_WRITE" 5 "EEPROM_BLOCK_PROTECT" 6 "EEPROM_READ_IDENTIFICATION_PAGE" 7 "EEPROM_WRITE_IDENTIFICATION_PAGE" 8 "EEPROM_SUB_WRITE_IDENTIFICATION_PAGE" 9 "EEPROM_LOCK_IDENTIFICATION_PAGE" 10 "IO_SEND_FRAME" 11 "SBC_REFRESH_WATCHDOG" 12 "RESERVED_1" 13 "RESERVED_2" 14 "RESERVED_3";
VAL_ 123 mutexRequestingSource 0 "ADC_REQUEST_VOLTAGE" 1 "ADC_GET_RESULT" 2 "EEPROM_READ" 3 "EEPROM_WRITE" 4 "EEPROM_SUB_WRITE" 5 "EEPROM_BLOCK_PROTECT" 6 "EEPROM_READ_IDENTIFICATION_PAGE" 7 "EEPROM_WRITE_IDENTIFICATION_PAGE" 8 "EEPROM_SUB_WRITE_IDENTIFICATION_PAGE" 9 "EEPROM_LOCK_IDENTIFICATION_PAGE" 10 "IO_SEND_FRAME" 11 "SBC_REFRESH_WATCHDOG" 12 "RESERVED_1" 13 "RESERVED_2" 14 "RESERVED_3";
VAL_ 124 mutexPostSource 0 "ADC_REQUEST_VOLTAGE" 1 "ADC_GET_RESULT" 2 "EEPROM_READ" 3 "EEPROM_WRITE" 4 "EEPROM_SUB_WRITE" 5 "EEPROM_BLOCK_PROTECT" 6 "EEPROM_READ_IDENTIFICATION_PAGE" 7 "EEPROM_WRITE_IDENTIFICATION_PAGE" 8 "EEPROM_SUB_WRITE_IDENTIFICATION_PAGE" 9 "EEPROM_LOCK_IDENTIFICATION_PAGE" 10 "IO_SEND_FRAME" 11 "SBC_REFRESH_WATCHDOG" 12 "RESERVED_1" 13 "RESERVED_2" 14 "RESERVED_3";
